# PLLCTRL_USB_OTG_SS register map
Vendor: Texas Instruments
Peripheral module from a debugger description file (folder omap5430_ES2_PUBLIC).
Registers are 32-bit, access per field, reset 0x0 unless marked. A register's access mark holds for its fields unless they carry their own. Offsets are as the file gives them; lines under a group give offsets from that group; [hi:lo] are bit positions; {n}, {i} and the like mark numbered series; 'fields as' and 'values as' point back to an identical list; <NAME> marks a mode.

## PLLCTRL_USB_OTG_SS
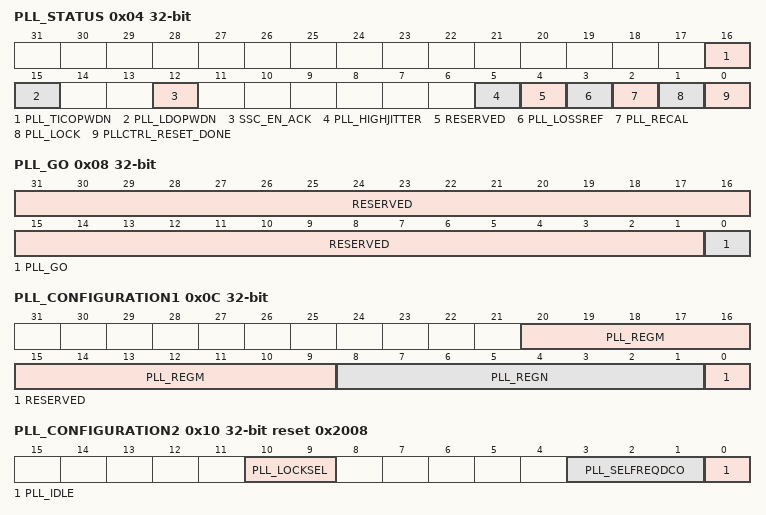
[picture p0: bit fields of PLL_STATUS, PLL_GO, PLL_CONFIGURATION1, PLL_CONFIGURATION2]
0x04 PLL_STATUS access not given — This register contains the status information
  [16] PLL_TICOPWDN ro — PLL TICOPWDN status.
    1=Internal_oscillator_power_down; 0=Internal_oscillator_power_up
  [15] PLL_LDOPWDN ro — PLL LDOPWDN status.
    1=PLL's_internal_LDO_is_power_down; 0=PLL's_internal_LDO_is_power_up
  [12] SSC_EN_ACK ro — Spread Spectrum Clocking acknowledge
    1=SSC_act (Spread Spectrum Clocking active); 0=SSC_inact (Spread Spectrum Clocking inactive)
  [5] PLL_HIGHJITTER ro — PLL High Jitter status
    1=High_Jiitter (PLL in high jitter condition: Phase error > 24%); 0=Normal_Jitter (PLL in normal jitter condition)
  [4] RESERVED ro — Read returns zero.
  [3] PLL_LOSSREF ro — PLL Reference Loss status
    1=Ref_Inp_Inact (Reference input inactive); 0=Ref_Inp_Act (Reference input active)
  [2] PLL_RECAL ro — PLL re-calibration status If this bit is active, the PLL needs to be re-calibrated
    1=Recal_required (Recalibration is required); 0=Recal_not_required (Recalibration is not required)
  [1] PLL_LOCK ro — PLL Lock status See the programming guide for the use of this bit
    1=DSI_PLL_Lock (PLL is locked); 0=DSI_PLL_NoLock (PLL is not locked)
  [0] PLLCTRL_RESET_DONE ro — PLLCTRL reset done status
    1=RDone (Reset has completed); 0=NotRD (Reset is in progress)
0x08 PLL_GO — This register contains the GO bit
  [31:1] RESERVED ro — Reads return zero.
  [0] PLL_GO rw — Request (re-)locking sequence of the PLL.
    0=Done (No pending action); 1=Go (Request PLL (re-)locking/locking pending)
0x0C PLL_CONFIGURATION1 — This register contains the latched PLL and HSDIVDER configuration bits
  [20:9] PLL_REGM rw — M Divider for PLL
  [8:1] PLL_REGN rw — N Divider for PLL (Reference)
  [0] RESERVED ro — Read returns zero.
0x10 PLL_CONFIGURATION2 reset 0x2008 — This register contains the unlatched PLL and HSDIVDER configuration bits These bits are 'shadowed' when automatic mode is selected
  [10:9] PLL_LOCKSEL rw — Selects the lock criteria for the PLLOther values: Reserved enum=SPARE .
    0=PHASELOCK; 1=FREQLOCK (Frequency Lock)
  [3:1] PLL_SELFREQDCO rw — DCO frequency range selector for DPLL_USB_OTG_SS 0x2 Set if DCO frequency is between 500MHz and 1000MHz 0x4 Set if DCO frequency is between 1000MHz and 2000MHz Other values: Reserved
  [0] PLL_IDLE rw
    0=IDLE_notsel (IDLE is not selected); 1=IDLE_sel (IDLE is selected)
0x14 PLL_CONFIGURATION3 — HSDIVIDER configuration bits for the M5 and M6 dividers
  [17:10] PLL_SD rw — Sigma delta divider setting for DPLL_USB_OTG_SS based on the PLL lock configuration.
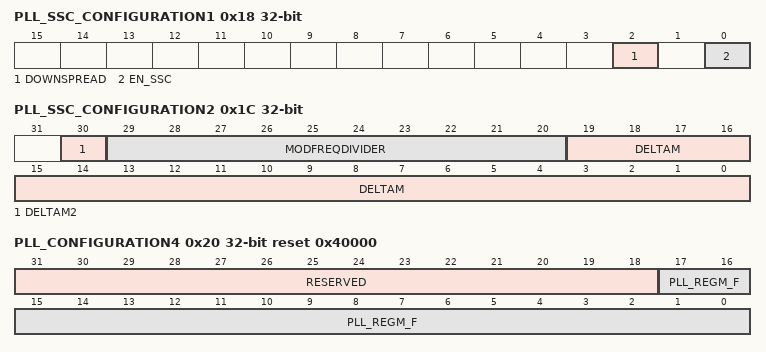
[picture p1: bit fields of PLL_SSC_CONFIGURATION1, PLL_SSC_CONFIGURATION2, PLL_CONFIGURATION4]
0x18 PLL_SSC_CONFIGURATION1 — Configuration for PLL Spread Spectrum Clocking modulation
  [2] DOWNSPREAD rw — Forces the clock spreading only in the down spectrum.
    0=NotForced (Clock spreading not forced.); 1=ForceDown (Spectrum spreading only in down direction.)
  [0] EN_SSC rw — Spread Spectrum Clocking enable
    0=SSC_Off (Spread Spectrum Clocking disabled); 1=SSC_On (Spread Spectrum Clocking enabled)
0x1C PLL_SSC_CONFIGURATION2
  [30] DELTAM2 rw — MSB of DeltaM control bus.
  [29:20] MODFREQDIVIDER rw — Modulation Frequency Divider control for SSC.
  [19:0] DELTAM rw — DeltaM control for SSC.
0x20 PLL_CONFIGURATION4 reset 0x40000 — Allows setting the fractional M divider and M2 divider for PLL.
  [31:18] RESERVED ro — Reads as 0x1
  [17:0] PLL_REGM_F rw — Fractional part of M divider.
